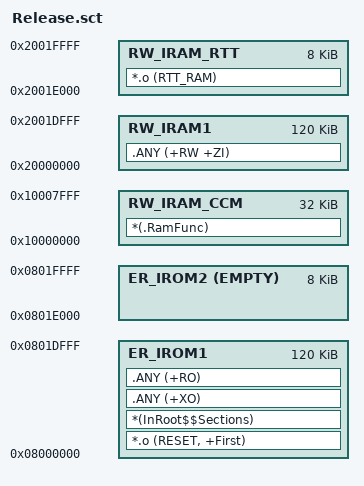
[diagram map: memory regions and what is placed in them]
LR_IROM1 0x08000000 0x0001E000  {  ; load_region size_region
  ER_IROM1 0x08000000 0x0001E000  {  ; load address = execution address
   *.o (RESET, +First)
   *(InRoot$$Sections)
   .ANY (+XO)
   .ANY (+RO)
  }

  RW_IRAM_CCM 0x10000000 0x00008000  {  ; 32KB CCM-SRAM for RAM functions
   *(.RamFunc)
  }

  ; RTT 专区：控制块 + UP0/UP1/Down 缓冲，段名 RTT_RAM（见 SEGGER_RTT_Conf.h / drv_rtt_stream.c）
  RW_IRAM_RTT 0x2001E000 0x00002000 { ; 8KB RTT RAM
   *.o (RTT_RAM)
  }

  RW_IRAM1 0x20000000 0x0001E000  {  ; 120KB main SRAM
   .ANY (+RW +ZI)
  }
}

LR_IROM2 0x0801E000 0x00002000  {  ; 8KB reserved for FEE
  ER_IROM2 0x0801E000 EMPTY 0x00002000  {  ; load address = execution address

  }
}

/*-Start of  regions- Auto-generated By STM32CubeMX-*/
